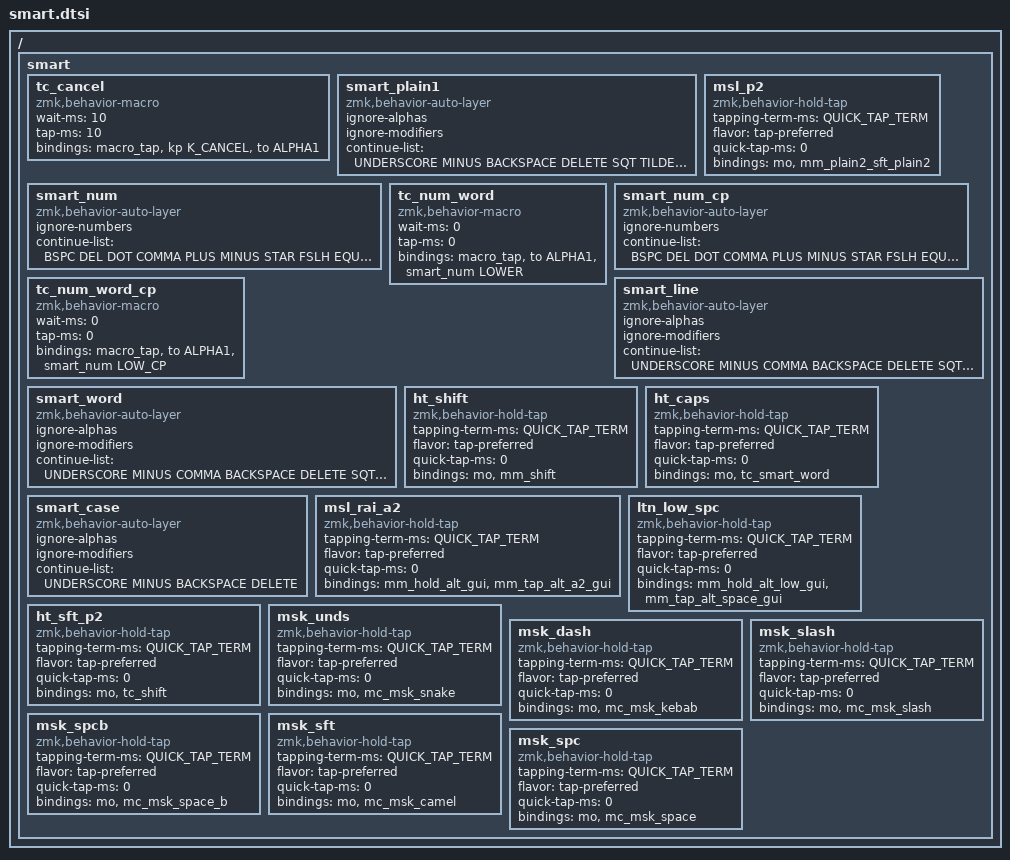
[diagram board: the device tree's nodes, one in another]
/*
*
* Copyright (c) 2022 Rafael Romão
* SPDX-License-Identifier: MIT
*
*/

/ {
    smart {
        
        // ********************** CANCEL ********************** //

        tc_cancel: tc_cancel {
			compatible = "zmk,behavior-macro";
            #binding-cells = <0>;
            wait-ms = <10>;
            tap-ms = <10>;
            bindings = <&macro_tap &kp K_CANCEL &to ALPHA1>;
        };
        LAYERTAP_TP(th_cancel,     &tc_cancel)

        // ********************** SMART PLAIN ALPHAS ********************** //

        smart_plain1: smart_plain1 {
            compatible = "zmk,behavior-auto-layer";
            ignore-alphas;
            ignore-modifiers;
			#binding-cells = <1>;
            continue-list = <UNDERSCORE MINUS BACKSPACE DELETE SQT TILDE CARET GRAVE SPACE>;
        };

        MACRO(tc_smart_plain1, &smart_plain1 PLAIN1)

        MACRO(mc_plain2, &sl PLAIN2)
        MACRO(mc_shifted_plain2, &sl SFT_PLAIN2)
        MOD_MORPH(mm_plain2_sft_plain2, MOD_LSFT|MOD_RSFT, &mc_shifted_plain2, &mc_plain2)

        msl_p2: msl_p2 {
            compatible = "zmk,behavior-hold-tap";
            #binding-cells = <2>;
            tapping-term-ms = <QUICK_TAP_TERM>;
            flavor = "tap-preferred";
            quick-tap-ms = <0>;
            bindings = <&mo>, <&mm_plain2_sft_plain2>;
        };

        // ********************** NUM WORD ********************** //

        smart_num: smart_num {
            compatible = "zmk,behavior-auto-layer";
            ignore-numbers;
			#binding-cells = <1>;
            continue-list = <BSPC DEL DOT COMMA PLUS MINUS STAR FSLH EQUAL AMPS PIPE HASH TILDE CARET LEFT RIGHT HOME END 
                             LBRC RBRC BACKSLASH DOLLAR AT LPAR RPAR DQT SQT LBKT RBKT QMARK GRAVE>;
        };

        tc_num_word: tc_num_word {
			compatible = "zmk,behavior-macro";
            #binding-cells = <0>;
            wait-ms = <0>;
            tap-ms = <0>;
            bindings = <&macro_tap &to ALPHA1 &smart_num LOWER>;
        };

        LAYERTAP_TP(ht_num_word, &tc_num_word)

        smart_num_cp: smart_num_cp {
            compatible = "zmk,behavior-auto-layer";
            ignore-numbers;
			#binding-cells = <1>;
            continue-list = <BSPC DEL DOT COMMA PLUS MINUS STAR FSLH EQUAL AMPS PIPE HASH TILDE CARET
                             LBRC RBRC BACKSLASH DOLLAR AT LPAR RPAR DQT SQT LBKT RBKT QMARK GRAVE>;
        };

        tc_num_word_cp: tc_num_word_cp {
			compatible = "zmk,behavior-macro";
            #binding-cells = <0>;
            wait-ms = <0>;
            tap-ms = <0>;
            bindings = <&macro_tap &to ALPHA1 &smart_num LOW_CP>;
        };

        // ******************* CAPS LINE ******************* //

        smart_line: smart_line {
            compatible = "zmk,behavior-auto-layer";
            ignore-alphas;
            ignore-modifiers;
			#binding-cells = <1>;  
            continue-list = <UNDERSCORE MINUS COMMA BACKSPACE DELETE SQT TILDE CARET GRAVE SPACE>;
        };
        MACRO(tc_smart_line, &smart_line CPLK_A1)

        // ******************* CAPS WORD ******************* //

        smart_word: smart_word {
            compatible = "zmk,behavior-auto-layer";
            ignore-alphas;
            ignore-modifiers;
			#binding-cells = <1>;  
            continue-list = <UNDERSCORE MINUS COMMA BACKSPACE DELETE SQT TILDE CARET GRAVE>;
        };
        MACRO(tc_smart_word, &smart_word CASE_A1)

        // ******************* SMART SHIFT ******************* //

        MACRO(tc_shift, &sk LSHFT)
        MOD_MORPH(mm_shift, MOD_LSFT|MOD_RSFT, &tc_smart_word, &tc_shift)
        MOD_MORPH(mm_repeat, MOD_LSFT|MOD_RSFT, &tc_smart_line, &alternate_repeat_key)

        ht_shift: ht_shift {
            compatible = "zmk,behavior-hold-tap";
            #binding-cells = <2>;
            tapping-term-ms = <QUICK_TAP_TERM>;
            flavor = "tap-preferred";
            quick-tap-ms = <0>;
            bindings = <&mo>, <&mm_shift>;
        };

        ht_caps: ht_caps {
            compatible = "zmk,behavior-hold-tap";
            #binding-cells = <2>;
            tapping-term-ms = <QUICK_TAP_TERM>;
            flavor = "tap-preferred";
            quick-tap-ms = <0>;
            bindings = <&mo>, <&tc_smart_word>;
        };

        // ******************** SMART CASES ******************** //

        smart_case: smart_case {
            compatible = "zmk,behavior-auto-layer";
            ignore-alphas;
            ignore-modifiers;
			#binding-cells = <1>;  
            continue-list = <UNDERSCORE MINUS BACKSPACE DELETE>;
        };
        MACRO(tc_constant_case, &smart_case CONST_CASE)
        MACRO(tc_snake_case, &smart_case SNAKE_CASE)
        MACRO(tc_kebab_case, &smart_case KEBAB_CASE)
        MACRO(tc_camel_case, &smart_case CAMEL_CASE)
        MACRO(tc_slash_case, &smart_case SLASH_CASE)
        MACRO(tc_pascal_case,  &tc_camel_case &sk LSHFT)





        MACRO(mc_msk_camel, &sl CASE_A1)
        MACRO(mc_msk_snake, &kp UNDERSCORE &sl SPACING)
        MACRO(mc_msk_kebab, &kp MINUS &sl SPACING)
        MACRO(mc_msk_slash, &kp SLASH &sl SPACING)
        MACRO(mc_msk_space, &kp SPACE &to ALPHA1)
        MACRO(mc_msk_space_b, &kp BACKSPACE &kp SPACE &to ALPHA1)

        MACRO(mc_alpha2, &sl ALPHA2)
        MACRO(mc_sft_a2, &sl SFT_A2)
        MOD_MORPH(mm_alpha2_shifted2, MOD_LSFT|MOD_RSFT, &mc_sft_a2, &mc_alpha2)

        MACRO(mc_case_a2,    &sl CASE_A2)
        LAYERTAP_TP(th_sft_a2,  &mc_sft_a2)
        LAYERTAP_TP(th_case_a2, &mc_case_a2)

        MACRO(mc_sk_rgui, &sk RGUI)
        MACRO(mc_hold_raise, &macro_press &mo RAISE &macro_pause_for_release &macro_release &mo RAISE)
        MACRO(mc_hold_rgui, &macro_press &kp RGUI &macro_pause_for_release &macro_release &kp RGUI)
        MOD_MORPH_KM(mm_hold_sft_rai_gui, MOD_LSFT, &mc_hold_rgui, &mc_hold_raise)
        MOD_MORPH_KM(mm_hold_ctl_rai_gui, MOD_LCTL, &mm_hold_sft_rai_gui, &mc_hold_raise)
        MOD_MORPH_KM(mm_hold_alt_gui, MOD_LALT, &mm_hold_ctl_rai_gui, &mc_hold_raise)
        MOD_MORPH_KM(mm_tap_sft_a2_gui, MOD_LSFT, &mc_sk_rgui, &mm_alpha2_shifted2)
        MOD_MORPH_KM(mm_tap_ctl_a2_gui, MOD_LCTL, &mm_tap_sft_a2_gui, &mm_alpha2_shifted2)
        MOD_MORPH_KM(mm_tap_alt_a2_gui, MOD_LALT, &mm_tap_ctl_a2_gui, &mm_alpha2_shifted2)

        msl_rai_a2: msl_rai_a2 {
            compatible = "zmk,behavior-hold-tap";
            #binding-cells = <2>;
            tapping-term-ms = <QUICK_TAP_TERM>;
            flavor = "tap-preferred";
            quick-tap-ms = <0>;
            bindings = <&mm_hold_alt_gui>, <&mm_tap_alt_a2_gui>;
        };

        MACRO(mc_space, &ak_space)
        MACRO(mc_sk_lgui, &sk LGUI)
        MACRO(mc_hold_lower, &macro_press &mo LOWER &macro_pause_for_release &macro_release &mo LOWER)
        MACRO(mc_hold_lgui, &macro_press &kp LGUI &macro_pause_for_release &macro_release &kp LGUI)
        MOD_MORPH_KM(mm_hold_sft_low_gui, MOD_RSFT, &mc_hold_lgui, &mc_hold_lower)
        MOD_MORPH_KM(mm_hold_ctl_low_gui, MOD_RCTL, &mm_hold_sft_low_gui, &mc_hold_lower)
        MOD_MORPH_KM(mm_hold_alt_low_gui, MOD_RALT, &mm_hold_ctl_low_gui, &mc_hold_lower)
        MOD_MORPH_KM(mm_tap_sft_space_gui, MOD_RSFT, &mc_sk_lgui, &mc_space)
        MOD_MORPH_KM(mm_tap_ctl_space_gui, MOD_RCTL, &mm_tap_sft_space_gui, &mc_space)
        MOD_MORPH_KM(mm_tap_alt_space_gui, MOD_RALT, &mm_tap_ctl_space_gui, &mc_space)

        ltn_low_spc: ltn_low_spc {
            compatible = "zmk,behavior-hold-tap";
            #binding-cells = <2>;
            tapping-term-ms = <QUICK_TAP_TERM>;
            flavor = "tap-preferred";
            quick-tap-ms = <0>;
            bindings = <&mm_hold_alt_low_gui>, <&mm_tap_alt_space_gui>;
        };

        ht_sft_p2: ht_sft_p2 {
            compatible = "zmk,behavior-hold-tap";
            #binding-cells = <2>;
            tapping-term-ms = <QUICK_TAP_TERM>;
            flavor = "tap-preferred";
            quick-tap-ms = <0>;
            bindings = <&mo>, <&tc_shift>;
        };

        msk_unds: msk_unds {
            compatible = "zmk,behavior-hold-tap";
            #binding-cells = <2>;
            tapping-term-ms = <QUICK_TAP_TERM>;
            flavor = "tap-preferred";
            quick-tap-ms = <0>;
            bindings = <&mo>, <&mc_msk_snake>;
        };

        msk_dash: msk_dash {
            compatible = "zmk,behavior-hold-tap";
            #binding-cells = <2>;
            tapping-term-ms = <QUICK_TAP_TERM>;
            flavor = "tap-preferred";
            quick-tap-ms = <0>;
            bindings = <&mo>, <&mc_msk_kebab>;
        };

        msk_slash: msk_slash {
            compatible = "zmk,behavior-hold-tap";
            #binding-cells = <2>;
            tapping-term-ms = <QUICK_TAP_TERM>;
            flavor = "tap-preferred";
            quick-tap-ms = <0>;
            bindings = <&mo>, <&mc_msk_slash>;
        };

        msk_spcb: msk_spcb {
            compatible = "zmk,behavior-hold-tap";
            #binding-cells = <2>;
            tapping-term-ms = <QUICK_TAP_TERM>;
            flavor = "tap-preferred";
            quick-tap-ms = <0>;
            bindings = <&mo>, <&mc_msk_space_b>;
        };

        msk_sft: msk_sft {
            compatible = "zmk,behavior-hold-tap";
            #binding-cells = <2>;
            tapping-term-ms = <QUICK_TAP_TERM>;
            flavor = "tap-preferred";
            quick-tap-ms = <0>;
            bindings = <&mo>, <&mc_msk_camel>;
        };

        msk_spc: msk_spc {
            compatible = "zmk,behavior-hold-tap";
            #binding-cells = <2>;
            tapping-term-ms = <QUICK_TAP_TERM>;
            flavor = "tap-preferred";
            quick-tap-ms = <0>;
            bindings = <&mo>, <&mc_msk_space>;
        };

    };
};
